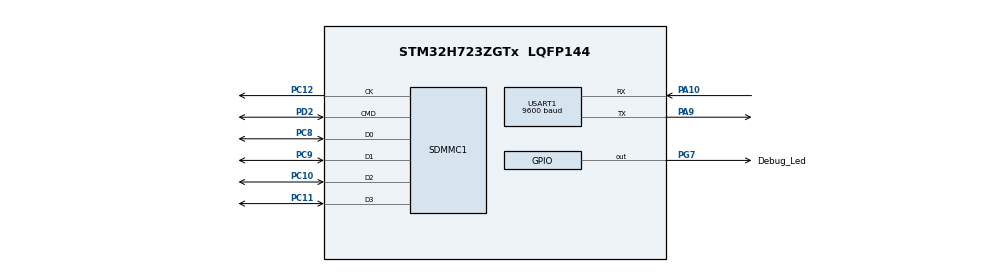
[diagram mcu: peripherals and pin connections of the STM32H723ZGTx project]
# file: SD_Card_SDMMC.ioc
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CORTEX_M7.default_mode_Activation=1
FATFS._MAX_SS=4096
FATFS._USE_LFN=3
Mcu.Family=STM32H7
Mcu.Name=STM32H723ZGTx
Mcu.Package=LQFP144
NVIC.PriorityGroup=NVIC_PRIORITYGROUP_4
NVIC.SDMMC1_IRQn=true\:0\:0\:false\:false\:true\:true\:true\:true
PA10.Mode=Asynchronous
PA10.Signal=USART1_RX
PA13(JTMS/SWDIO).Mode=Serial_Wire
PA13(JTMS/SWDIO).Signal=DEBUG_JTMS-SWDIO
PA14(JTCK/SWCLK).Mode=Serial_Wire
PA14(JTCK/SWCLK).Signal=DEBUG_JTCK-SWCLK
PA9.Mode=Asynchronous
PA9.Signal=USART1_TX
PC10.Mode=SD_4_bits_Wide_bus
PC10.Signal=SDMMC1_D2
PC11.Mode=SD_4_bits_Wide_bus
PC11.Signal=SDMMC1_D3
PC12.Mode=SD_4_bits_Wide_bus
PC12.Signal=SDMMC1_CK
PC8.Mode=SD_4_bits_Wide_bus
PC8.Signal=SDMMC1_D0
PC9.Mode=SD_4_bits_Wide_bus
PC9.Signal=SDMMC1_D1
PD2.Mode=SD_4_bits_Wide_bus
PD2.Signal=SDMMC1_CMD
PG7.GPIO_Label=Debug_Led
PG7.Signal=GPIO_Output
PH0-OSC_IN.Mode=HSE-External-Oscillator
PH0-OSC_IN.Signal=RCC_OSC_IN
PH1-OSC_OUT.Mode=HSE-External-Oscillator
PH1-OSC_OUT.Signal=RCC_OSC_OUT
ProjectManager.HeapSize=0x200
ProjectManager.StackSize=0x400
ProjectManager.TargetToolchain=CMake
RCC.ADCFreq_Value=129000000
RCC.APB1Freq_Value=108000000
RCC.APB2Freq_Value=108000000
RCC.APB3Freq_Value=108000000
RCC.APB4Freq_Value=108000000
RCC.CortexFreq_Value=216000000
RCC.D1PPRE=RCC_APB3_DIV2
RCC.D2PPRE1=RCC_APB1_DIV2
RCC.D2PPRE2=RCC_APB2_DIV2
RCC.D3PPRE=RCC_APB4_DIV2
RCC.DIVM1=4
RCC.DIVN1=13
RCC.DIVP1=1
RCC.DIVQ1=6
RCC.HCLKFreq_Value=216000000
RCC.PLL2FRACN=0
RCC.PLL3FRACN=0
RCC.PLLFRACN=4096
RCC.SYSCLKFreq_VALUE=216000000
RCC.SYSCLKSource=RCC_SYSCLKSOURCE_PLLCLK
RCC.USBFreq_Value=36000000
SDMMC1.ClockDiv=1
USART1.BaudRate=9600
USART1.VirtualMode-Asynchronous=VM_ASYNC
VP_FATFS_VS_SDIO.Mode=SDIO
VP_MEMORYMAP_VS_MEMORYMAP.Mode=CurAppReg
board=custom

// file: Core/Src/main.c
/* USER CODE BEGIN Header */
/**
 ******************************************************************************
 * @file           : main.c
 * @brief          : Main program body
 ******************************************************************************
 * @attention
 *
 * Copyright (c) 2025 STMicroelectronics.
 * All rights reserved.
 *
 * This software is licensed under terms that can be found in the LICENSE file
 * in the root directory of this software component.
 * If no LICENSE file comes with this software, it is provided AS-IS.
 *
 ******************************************************************************
 */
/* USER CODE END Header */
#include "main.h"
#include "fatfs.h"

/* USER CODE BEGIN Includes */

#include "sdio_functions.h"
/* USER CODE END Includes */

SD_HandleTypeDef hsd1;

UART_HandleTypeDef huart1;

void SystemClock_Config(void);
static void MPU_Config(void);
static void MX_GPIO_Init(void);
static void MX_SDMMC1_SD_Init(void);
static void MX_USART1_UART_Init(void);

/* USER CODE BEGIN 0 */
int _write(int fd, unsigned char *buf, int len) {
  if (fd == 1 || fd == 2) {                     // stdout or stderr ?
    HAL_UART_Transmit(&huart1, buf, len, 999);  // Print to the UART
  }
  return len;
}
uint8_t bufr[5120];
UINT br;
/* USER CODE END 0 */

int main(void)
{

  /* MPU Configuration--------------------------------------------------------*/
  MPU_Config();

  /* MCU Configuration--------------------------------------------------------*/

  /* Reset of all peripherals, Initializes the Flash interface and the Systick. */
  HAL_Init();

  /* Configure the system clock */
  SystemClock_Config();

  /* Initialize all configured peripherals */
  MX_GPIO_Init();
  MX_FATFS_Init();
  MX_SDMMC1_SD_Init();
  MX_USART1_UART_Init();
  /* USER CODE BEGIN 2 */
  HAL_Delay(3000);
  // sd_benchmark();
 sd_mount();
// sd_read_file("family_guy_rgb565_120s_be_320x240.rgb", bufr, 5120, &br);
 sd_unmount();

  /* USER CODE END 2 */

  /* Infinite loop */
  /* USER CODE BEGIN WHILE */
    while (1)
    {
      HAL_GPIO_TogglePin(Debug_Led_GPIO_Port,Debug_Led_Pin);
      HAL_Delay(200);
    /* USER CODE END WHILE */

    }
}

void SystemClock_Config(void)
{
  RCC_OscInitTypeDef RCC_OscInitStruct = {0};
  RCC_ClkInitTypeDef RCC_ClkInitStruct = {0};

  /** Supply configuration update enable
  */
  HAL_PWREx_ConfigSupply(PWR_LDO_SUPPLY);

  /** Configure the main internal regulator output voltage
  */
  __HAL_PWR_VOLTAGESCALING_CONFIG(PWR_REGULATOR_VOLTAGE_SCALE0);

  while(!__HAL_PWR_GET_FLAG(PWR_FLAG_VOSRDY)) {}

  /** Initializes the RCC Oscillators according to the specified parameters
  * in the RCC_OscInitTypeDef structure.
  */
  RCC_OscInitStruct.OscillatorType = RCC_OSCILLATORTYPE_HSI;
  RCC_OscInitStruct.HSIState = RCC_HSI_DIV1;
  RCC_OscInitStruct.HSICalibrationValue = 64;
  RCC_OscInitStruct.PLL.PLLState = RCC_PLL_ON;
  RCC_OscInitStruct.PLL.PLLSource = RCC_PLLSOURCE_HSI;
  RCC_OscInitStruct.PLL.PLLM = 4;
  RCC_OscInitStruct.PLL.PLLN = 13;
  RCC_OscInitStruct.PLL.PLLP = 1;
  RCC_OscInitStruct.PLL.PLLQ = 6;
  RCC_OscInitStruct.PLL.PLLR = 2;
  RCC_OscInitStruct.PLL.PLLRGE = RCC_PLL1VCIRANGE_3;
  RCC_OscInitStruct.PLL.PLLVCOSEL = RCC_PLL1VCOWIDE;
  RCC_OscInitStruct.PLL.PLLFRACN = 4096;
  if (HAL_RCC_OscConfig(&RCC_OscInitStruct) != HAL_OK)
  {
    Error_Handler();
  }

  /** Initializes the CPU, AHB and APB buses clocks
  */
  RCC_ClkInitStruct.ClockType = RCC_CLOCKTYPE_HCLK|RCC_CLOCKTYPE_SYSCLK
                              |RCC_CLOCKTYPE_PCLK1|RCC_CLOCKTYPE_PCLK2
                              |RCC_CLOCKTYPE_D3PCLK1|RCC_CLOCKTYPE_D1PCLK1;
  RCC_ClkInitStruct.SYSCLKSource = RCC_SYSCLKSOURCE_PLLCLK;
  RCC_ClkInitStruct.SYSCLKDivider = RCC_SYSCLK_DIV1;
  RCC_ClkInitStruct.AHBCLKDivider = RCC_HCLK_DIV1;
  RCC_ClkInitStruct.APB3CLKDivider = RCC_APB3_DIV2;
  RCC_ClkInitStruct.APB1CLKDivider = RCC_APB1_DIV2;
  RCC_ClkInitStruct.APB2CLKDivider = RCC_APB2_DIV2;
  RCC_ClkInitStruct.APB4CLKDivider = RCC_APB4_DIV2;

  if (HAL_RCC_ClockConfig(&RCC_ClkInitStruct, FLASH_LATENCY_3) != HAL_OK)
  {
    Error_Handler();
  }
}

static void MX_SDMMC1_SD_Init(void)
{

  hsd1.Instance = SDMMC1;
  hsd1.Init.ClockEdge = SDMMC_CLOCK_EDGE_RISING;
  hsd1.Init.ClockPowerSave = SDMMC_CLOCK_POWER_SAVE_DISABLE;
  hsd1.Init.BusWide = SDMMC_BUS_WIDE_4B;
  hsd1.Init.HardwareFlowControl = SDMMC_HARDWARE_FLOW_CONTROL_DISABLE;
  hsd1.Init.ClockDiv = 1;
  if (HAL_SD_Init(&hsd1) != HAL_OK)
  {
    Error_Handler();
  }
  /* USER CODE BEGIN SDMMC1_Init 2 */
  // hsd1.Init.BusWide = SDMMC_BUS_WIDE_1B;
  /* USER CODE END SDMMC1_Init 2 */

}

static void MX_USART1_UART_Init(void)
{

  huart1.Instance = USART1;
  huart1.Init.BaudRate = 9600;
  huart1.Init.WordLength = UART_WORDLENGTH_8B;
  huart1.Init.StopBits = UART_STOPBITS_1;
  huart1.Init.Parity = UART_PARITY_NONE;
  huart1.Init.Mode = UART_MODE_TX_RX;
  huart1.Init.HwFlowCtl = UART_HWCONTROL_NONE;
  huart1.Init.OverSampling = UART_OVERSAMPLING_16;
  huart1.Init.OneBitSampling = UART_ONE_BIT_SAMPLE_DISABLE;
  huart1.Init.ClockPrescaler = UART_PRESCALER_DIV1;
  huart1.AdvancedInit.AdvFeatureInit = UART_ADVFEATURE_NO_INIT;
  if (HAL_UART_Init(&huart1) != HAL_OK)
  {
    Error_Handler();
  }
  if (HAL_UARTEx_SetTxFifoThreshold(&huart1, UART_TXFIFO_THRESHOLD_1_8) != HAL_OK)
  {
    Error_Handler();
  }
  if (HAL_UARTEx_SetRxFifoThreshold(&huart1, UART_RXFIFO_THRESHOLD_1_8) != HAL_OK)
  {
    Error_Handler();
  }
  if (HAL_UARTEx_DisableFifoMode(&huart1) != HAL_OK)
  {
    Error_Handler();
  }

}

static void MX_GPIO_Init(void)
{
  GPIO_InitTypeDef GPIO_InitStruct = {0};

  /* GPIO Ports Clock Enable */
  __HAL_RCC_GPIOH_CLK_ENABLE();
  __HAL_RCC_GPIOG_CLK_ENABLE();
  __HAL_RCC_GPIOC_CLK_ENABLE();
  __HAL_RCC_GPIOA_CLK_ENABLE();
  __HAL_RCC_GPIOD_CLK_ENABLE();

  /*Configure GPIO pin Output Level */
  HAL_GPIO_WritePin(Debug_Led_GPIO_Port, Debug_Led_Pin, GPIO_PIN_RESET);

  /*Configure GPIO pin : Debug_Led_Pin */
  GPIO_InitStruct.Pin = Debug_Led_Pin;
  GPIO_InitStruct.Mode = GPIO_MODE_OUTPUT_PP;
  GPIO_InitStruct.Pull = GPIO_NOPULL;
  GPIO_InitStruct.Speed = GPIO_SPEED_FREQ_LOW;
  HAL_GPIO_Init(Debug_Led_GPIO_Port, &GPIO_InitStruct);

}

 /* MPU Configuration */

void MPU_Config(void)
{
  MPU_Region_InitTypeDef MPU_InitStruct = {0};

  /* Disables the MPU */
  HAL_MPU_Disable();

  /** Initializes and configures the Region and the memory to be protected
  */
  MPU_InitStruct.Enable = MPU_REGION_ENABLE;
  MPU_InitStruct.Number = MPU_REGION_NUMBER0;
  MPU_InitStruct.BaseAddress = 0x0;
  MPU_InitStruct.Size = MPU_REGION_SIZE_4GB;
  MPU_InitStruct.SubRegionDisable = 0x87;
  MPU_InitStruct.TypeExtField = MPU_TEX_LEVEL0;
  MPU_InitStruct.AccessPermission = MPU_REGION_NO_ACCESS;
  MPU_InitStruct.DisableExec = MPU_INSTRUCTION_ACCESS_DISABLE;
  MPU_InitStruct.IsShareable = MPU_ACCESS_SHAREABLE;
  MPU_InitStruct.IsCacheable = MPU_ACCESS_NOT_CACHEABLE;
  MPU_InitStruct.IsBufferable = MPU_ACCESS_NOT_BUFFERABLE;

  HAL_MPU_ConfigRegion(&MPU_InitStruct);
  /* Enables the MPU */
  HAL_MPU_Enable(MPU_PRIVILEGED_DEFAULT);

}

void Error_Handler(void)
{
    __disable_irq();
    while (1)
    {
    }
}
